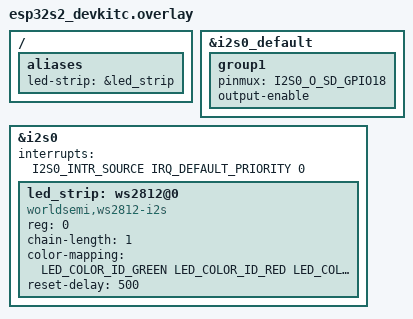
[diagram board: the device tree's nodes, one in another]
/*
 * Copyright (c) 2025 Espressif Systems (Shanghai) Co., Ltd.
 *
 * SPDX-License-Identifier: Apache-2.0
 */

#include <zephyr/dt-bindings/led/led.h>

/ {
	aliases {
		led-strip = &led_strip;
	};
};

&i2s0_default {
	group1 {
		pinmux = <I2S0_O_SD_GPIO18>;
		output-enable;
	};
};

i2s_led: &i2s0 {
	status = "okay";

	interrupts = <I2S0_INTR_SOURCE IRQ_DEFAULT_PRIORITY 0>;
	interrupt-names = "tx";

	led_strip: ws2812@0 {
		compatible = "worldsemi,ws2812-i2s";
		reg = <0>;

		chain-length = <1>;
		color-mapping = <LED_COLOR_ID_GREEN
				 LED_COLOR_ID_RED
				 LED_COLOR_ID_BLUE>;
		reset-delay = <500>;
	};
};
